# STM32N645 register map
File version: 1.0
CPU: CM55 r0p1, little endian, no MPU, FPU, vendor SysTick, 8 interrupt priority bits
Registers are 32-bit, read-write, reset 0x0 unless marked. A register's access mark holds for its fields unless they carry their own. Offsets are from the block's base; [hi:lo] are bit positions.

## ADF — Audio digital filter
Base 0x42026000
Same registers: ADF_S 0x52026000
0x00 GCR — ADF global control register
  [0] TRGO — Trigger output control
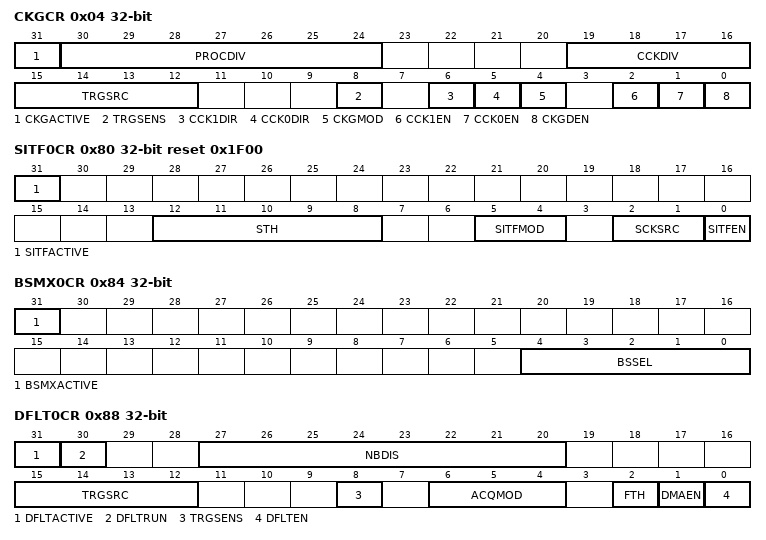
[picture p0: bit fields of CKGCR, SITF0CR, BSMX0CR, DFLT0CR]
0x04 CKGCR access per field — ADF clock generator control register
  [31] CKGACTIVE ro — Clock generator active flag
  [30:24] PROCDIV rw — Divider to control the serial interface clock
  [19:16] CCKDIV rw — Divider to control the ADF_CCK clock
  [15:12] TRGSRC rw — Digital filter trigger signal selection
  [8] TRGSENS rw — CKGEN trigger sensitivity selection
  [6] CCK1DIR rw — ADF_CCK1 direction
  [5] CCK0DIR rw — ADF_CCK0 direction
  [4] CKGMOD rw — Clock generator mode
  [2] CCK1EN rw — ADF_CCK1 clock enable
  [1] CCK0EN rw — ADF_CCK0 clock enable
  [0] CKGDEN rw — CKGEN dividers enable
0x80 SITF0CR access per field reset 0x1F00 — ADF serial interface control register 0
  [31] SITFACTIVE ro — Serial interface active flag
  [12:8] STH rw — Manchester symbol threshold/SPI threshold
  [5:4] SITFMOD rw — Serial interface type
  [2:1] SCKSRC rw — Serial clock source
  [0] SITFEN rw — Serial interface enable
0x84 BSMX0CR access per field — ADF bitstream matrix control register 0
  [31] BSMXACTIVE ro — BSMX active flag
  [4:0] BSSEL rw — Bitstream selection
0x88 DFLT0CR access per field — ADF digital filter control register 0
  [31] DFLTACTIVE ro — DFLT0 active flag
  [30] DFLTRUN ro — DFLT0 run status flag
  [27:20] NBDIS rw — Number of samples to be discarded
  [15:12] TRGSRC rw — DFLT0 trigger signal selection
  [8] TRGSENS rw — DFLT0 trigger sensitivity selection
  [6:4] ACQMOD rw — DFLT0 trigger mode
  [2] FTH rw — RXFIFO threshold selection
  [1] DMAEN rw — DMA requests enable
  [0] DFLTEN wo — DFLT0 enable
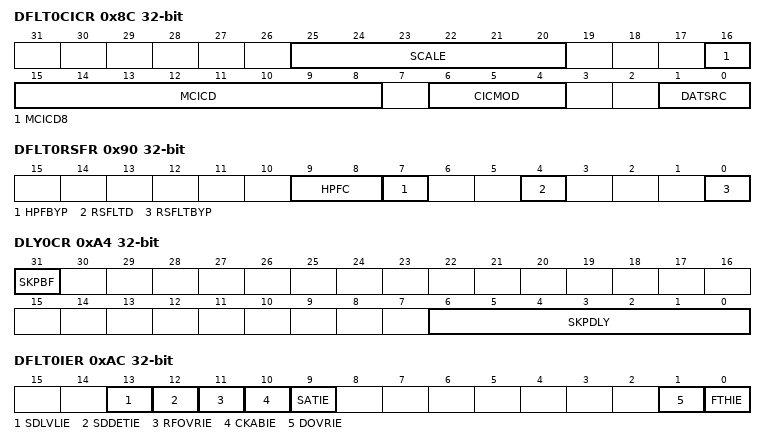
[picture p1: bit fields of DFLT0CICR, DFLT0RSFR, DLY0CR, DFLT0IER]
0x8C DFLT0CICR — ADF digital filer configuration register 0
  [25:20] SCALE — Scaling factor selection
  [16] MCICD8 — CIC decimation ratio selection
  [15:8] MCICD — CIC decimation ratio selection
  [6:4] CICMOD — Select the CIC order
  [1:0] DATSRC — Source data for the digital filter
0x90 DFLT0RSFR — ADF reshape filter configuration register 0
  [9:8] HPFC — High-pass filter cut-off frequency
  [7] HPFBYP — High-pass filter bypass
  [4] RSFLTD — Reshaper filter decimation ratio
  [0] RSFLTBYP — Reshaper filter bypass
0xA4 DLY0CR access per field — ADF delay control register 0
  [31] SKPBF ro — Skip busy flag
  [6:0] SKPDLY rw — Delay to apply to a bitstream
0xAC DFLT0IER — ADF DFLT0 interrupt enable register
  [13] SDLVLIE — SAD sound-level value ready enable
  [12] SDDETIE — Sound activity detection interrupt enable
  [11] RFOVRIE — Reshape filter overrun interrupt enable
  [10] CKABIE — Clock absence detection interrupt enable
  [9] SATIE — Saturation detection interrupt enable
  [1] DOVRIE — Data overflow interrupt enable
  [0] FTHIE — RXFIFO threshold interrupt enable
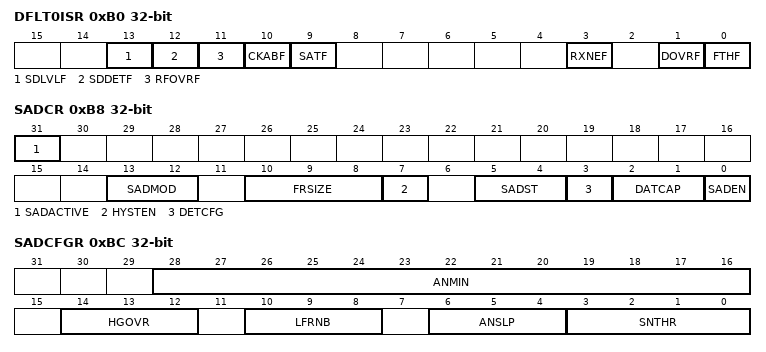
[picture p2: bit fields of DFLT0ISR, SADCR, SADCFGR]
0xB0 DFLT0ISR access per field — ADF DFLT0 interrupt status register 0
  [13] SDLVLF rw — Sound level value ready flag
  [12] SDDETF rw — Sound activity detection flag
  [11] RFOVRF rw — Reshape filter overrun detection flag
  [10] CKABF rw — Clock absence detection flag
  [9] SATF rw — Saturation detection flag
  [3] RXNEF ro — RXFIFO not empty flag
  [1] DOVRF rw — Data overflow flag
  [0] FTHF ro — RXFIFO threshold flag
0xB8 SADCR access per field — ADF SAD control register
  [31] SADACTIVE ro — SAD Active flag
  [13:12] SADMOD rw — SAD working mode
  [10:8] FRSIZE rw — Frame size
  [7] HYSTEN rw — Hysteresis enable
  [5:4] SADST ro — SAD state
  [3] DETCFG rw — Sound trigger event configuration
  [2:1] DATCAP rw — Data capture mode
  [0] SADEN rw — Sound activity detector enable
0xBC SADCFGR — ADF SAD configuration register
  [28:16] ANMIN — Minimum noise level
  [14:12] HGOVR — Hangover time window
  [10:8] LFRNB — Number of learning frames
  [6:4] ANSLP — Ambient noise slope control
  [3:0] SNTHR — Signal to noise threshold
0xC0 SADSDLVR ro — ADF SAD sound level register
  [14:0] SDLVL — Short term sound level
0xC4 SADANLVR ro — ADF SAD ambient noise level register
  [14:0] ANLVL — Ambient noise level estimation
0xF0 DFLT0DR ro — ADF digital filter data register 0
  [31:8] DR — Data processed by DFT0
